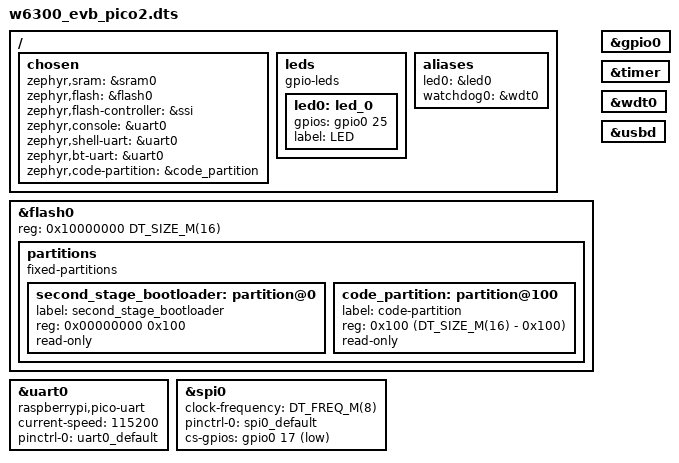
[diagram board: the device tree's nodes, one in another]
/*
 * Copyright (c) 2026 SUZINEE
 * SPDX-License-Identifier: Apache-2.0
 */

/dts-v1/;

#include <freq.h>

#include <raspberrypi/rpi_pico/rp2040.dtsi>
#include "w6300_evb_pico2-pinctrl.dtsi"

/ {
	chosen {
		zephyr,sram = &sram0;
		zephyr,flash = &flash0;
		zephyr,flash-controller = &ssi;
		zephyr,console = &uart0;
		zephyr,shell-uart = &uart0;
		zephyr,bt-uart = &uart0;
		zephyr,code-partition = &code_partition;
	};

	leds {
		compatible = "gpio-leds";

		led0: led_0 {
			gpios = <&gpio0 25 GPIO_ACTIVE_HIGH>;
			label = "LED";
		};
	};

	aliases {
		led0 = &led0;
		watchdog0 = &wdt0;
	};
};

&flash0 {
	reg = <0x10000000 DT_SIZE_M(16)>;

	partitions {
		compatible = "fixed-partitions";
		#address-cells = <1>;
		#size-cells = <1>;

		second_stage_bootloader: partition@0 {
			label = "second_stage_bootloader";
			reg = <0x00000000 0x100>;
			read-only;
		};

		code_partition: partition@100 {
			label = "code-partition";
			reg = <0x100 (DT_SIZE_M(16) - 0x100)>;
			read-only;
		};
	};
};

&uart0 {
	compatible = "raspberrypi,pico-uart";
	current-speed = <115200>;
	status = "okay";
	pinctrl-0 = <&uart0_default>;
	pinctrl-names = "default";
};

&gpio0 {
	status = "okay";
};

&spi0 {
	clock-frequency = <DT_FREQ_M(8)>;
	status = "okay";
	pinctrl-0 = <&spi0_default>;
	pinctrl-names = "default";
	cs-gpios = <&gpio0 17 GPIO_ACTIVE_LOW>;
};

&timer {
	status = "okay";
};

&wdt0 {
	status = "okay";
};

zephyr_udc0: &usbd {
	status = "okay";
};
